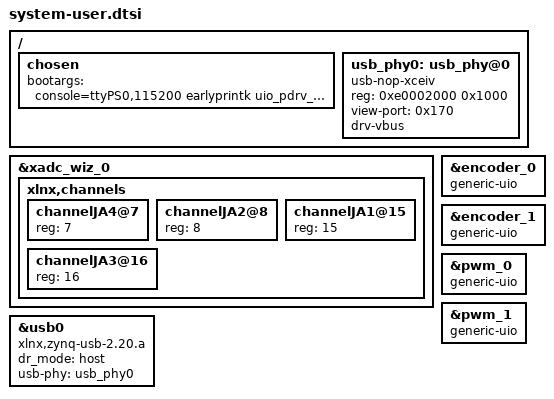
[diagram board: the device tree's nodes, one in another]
/include/ "system-conf.dtsi"
/ { 
	chosen {
        bootargs = "console=ttyPS0,115200 earlyprintk uio_pdrv_genirq.of_id=generic-uio root=/dev/mmcblk0p2 rw rootwait";
	};

	usb_phy0: usb_phy@0 {
	    compatible = "usb-nop-xceiv";
	    #phy-cells = <0>;
		reg = <0xe0002000 0x1000>;
		view-port=<0x170>;
		drv-vbus;
	};

};


&xadc_wiz_0 {
	xlnx,channels {
		#address-cells = <1>;
		#size-cells = <0>;
		channelJA4@7 {
			reg = <7>;
		};
		channelJA2@8 {
			reg = <8>;
		};
		channelJA1@15 {
			reg = <15>;
		};
		channelJA3@16 {
			reg = <16>;
		};
	};
};
 
&usb0 {
	compatible = "xlnx,zynq-usb-2.20.a", "chipidea,usb2";
	status = "okay";
	dr_mode = "host";
	usb-phy = <&usb_phy0>;
};

&encoder_0 {
	compatible = "generic-uio";
};
&encoder_1{
	compatible = "generic-uio";
};
&pwm_0 {
	compatible = "generic-uio";
};
&pwm_1{
	compatible = "generic-uio";
};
